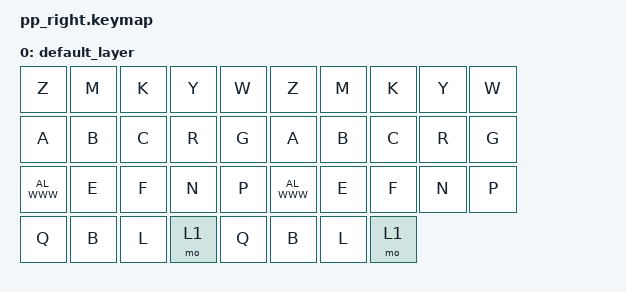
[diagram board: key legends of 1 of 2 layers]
#include <behaviors.dtsi>
#include <dt-bindings/zmk/bt.h>
#include <dt-bindings/zmk/keys.h>
#include <dt-bindings/zmk/outputs.h>

/ {
    combos {
        compatible = "zmk,combos";

        studio_unlock_combo {
            timeout-ms = <1000>;
            key-positions = <30 31>;
            bindings = <&studio_unlock>;
        };

        studio_unlock_combo_right {
            timeout-ms = <1000>;
            key-positions = <34 35>;
            bindings = <&studio_unlock>;
        };
    };

    keymap {
        compatible = "zmk,keymap";

        default_layer {
            bindings = <
                &kp Z    &kp M    &kp K    &kp Y    &kp W    &kp Z    &kp M    &kp K    &kp Y    &kp W
                &kp A    &kp B    &kp C    &kp R    &kp G    &kp A    &kp B    &kp C    &kp R    &kp G
                &kp C_AL_WWW    &kp E    &kp F    &kp N    &kp P    &kp C_AL_WWW    &kp E    &kp F    &kp N    &kp P
                &kp Q    &kp B    &kp L    &mo 1    &kp Q    &kp B    &kp L    &mo 1
            >;
        };

        fn_layer {
            display-name = "Fn";
            bindings = <
                &out OUT_BLE  &out OUT_USB  &bt BT_CLR  &bt BT_SEL 0  &bt BT_SEL 1    &out OUT_BLE  &out OUT_USB  &bt BT_CLR  &bt BT_SEL 0  &bt BT_SEL 1
                &trans        &trans       &trans        &trans        &trans          &trans        &trans       &trans        &trans        &trans
                &trans        &trans       &trans        &trans        &trans          &trans        &trans       &trans        &trans
                &trans        &trans       &trans        &trans          &trans        &trans       &trans        &trans
            >;
        };

        extra1 {
            status = "reserved";
        };

        extra2 {
            status = "reserved";
        };
    };
};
